# M369 register map
File version: 0.1
TOSHIBA Cortex-M3 MCU
CPU: 
Registers are 32-bit, read-write, reset 0x0 unless marked. A register's access mark holds for its fields unless they carry their own. Offsets are from the block's base; lines under a group give offsets from that group; [hi:lo] are bit positions; {n}, {i} and the like mark numbered series; 'fields as' and 'values as' point back to an identical list; <NAME> marks a mode.

## Memory map
{0x40005000+0x20*n} CANMB{n} size 0x4 (n=0..31) — CAN Controller (TXCAN) Mailbox RAM
0x40005400 CAN size 0x4 — CAN Controller (TXCAN)
0x40006000 HC size 0x58 — USB Host Controller (USBHC)
0x40008000 UDFS size 0x24 — UDC2 AHB Bridge
0x40008200 UDFS2 size 0x8 — UDC2(USB -Spec2.0 Device contoller)
0x4000A000 EM size 0x8 — UDC2 AHB Bridge
0x40040000 SSP0 size 0x28 — Synchronous Serial Port
0x40041000 SSP1 size 0x28 — Synchronous Serial Port
0x40042000 SSP2 size 0x28 — Synchronous Serial Port
0x40048000 UART4 size 0x8 — ARM Prime Cell PL011
0x40049000 UART5 size 0x8 — ARM Prime Cell PL011
0x4004C000 DMAA size 0x10 — DMA Controller
0x4004D000 DMAB size 0x10 — DMA Controller
0x40050000 ADA size 0x20 — Analog-to-Digital Converter (AD)
0x40051000 ADB size 0x20 — Analog-to-Digital Converter (AD)
0x40052000 ADILV size 0xC — Dual ADC Configuration
0x40054000 DA0 size 0x14 — Digital-to-Analog Converter (DA)
0x40055000 DA1 size 0x14 — Digital-to-Analog Converter (DA)
0x4005C000 EXB size 0x4 — External Bus Interface(EXB)
0x400C0000 PA size 0x1C — General Purpose Input_Output Port (PA)
0x400C0100 PB size 0x18 — General Purpose Input_Output Port (PB)
0x400C0200 PC size 0x10 — General Purpose Input_Output Port (PC)
0x400C0300 PD size 0xC — General Purpose Input_Output Port (PD)
0x400C0400 PE size 0x1C — General Purpose Input_Output Port (PE)
0x400C0500 PF size 0x18 — General Purpose Input_Output Port (PF)
0x400C0600 PG size 0x18 — General Purpose Input_Output Port (PG)
0x400C0700 PH size 0x1C — General Purpose Input_Output Port (PH)
0x400C0800 PI size 0x10 — General Purpose Input_Output Port (PI)
0x400C0900 PJ size 0x8 — General Purpose Input_Output Port (PJ)
0x400C0A00 PK size 0x18 — General Purpose Input_Output Port (PK)
0x400C0B00 PL size 0x20 — General Purpose Input_Output Port (PL)
0x400C0C00 PM size 0x10 — General Purpose Input_Output Port (PM)
0x400C0D00 PN size 0x10 — General Purpose Input_Output Port (PN)
{0x400C4000+0x100*n} TB{n} size 0x34 (n=0..7) — 16-bit Timer_Event Counter (TB)
0x400C7000 MT0 size 0x58 — 16-bit Multi-Purpose Timer (MPT-TMR_IGBT)
0x400C7100 MT1 size 0x58 — 16-bit Multi-Purpose Timer (MPT-TMR_IGBT)
0x400C7200 MT2 size 0x58 — 16-bit Multi-Purpose Timer (MPT-TMR_IGBT)
0x400C7300 MT3 size 0x58 — 16-bit Multi-Purpose Timer (MPT-TMR_IGBT)
0x400CC000 RTC size 0x3 — Real Time Clock (RTC)
0x400E0000 SBI0 size 0x18 — Serial Bus Interface (SBI)
0x400E0100 SBI1 size 0x18 — Serial Bus Interface (SBI)
0x400E0200 SBI2 size 0x18 — Serial Bus Interface (SBI)
0x400E1000 SC0 size 0x34 — Serial Channel (SC)
0x400E1100 SC1 size 0x34 — Serial Channel (SC)
0x400E1200 SC2 size 0x34 — Serial Channel (SC)
0x400E1300 SC3 size 0x34 — Serial Channel (SC)
0x400E7000 RMC size 0x38 — Remote Control Signal Preprocessor (RMC)
0x400F1000 OFD size 0x24 — Oscillation Frequency Detector (OFD)
0x400F2000 WD size 0x8 — Watchdog Timer (WD)
0x400F3000 CG size 0x10 — Clock Generator (CG)
0x400F3100 USBPLL size 0xC — Low Voltage detector control register
0x400F3200 TRMOSC size 0x10 — Low Voltage detector control register
0x400F4000 LVD size 0xC — Low Voltage detector control register
0x400F6000 MTPD0 size 0x24 — 16-bit Multi-Purpose Timer (MPT-PMD)
0x400F6100 MTPD1 size 0x24 — 16-bit Multi-Purpose Timer (MPT-PMD)
0x400F7000 EN0 size 0x10 — Encoder Input (ENC)
0x400F7100 EN1 size 0x10 — Encoder Input (ENC)
0x41FFF000 FC — Flash Control (FC)

## CANMB0 — CAN Controller (TXCAN) Mailbox RAM
Base 0x40005000
Same registers: CANMB{n} {0x40005000+0x20*n} (n=1..30)
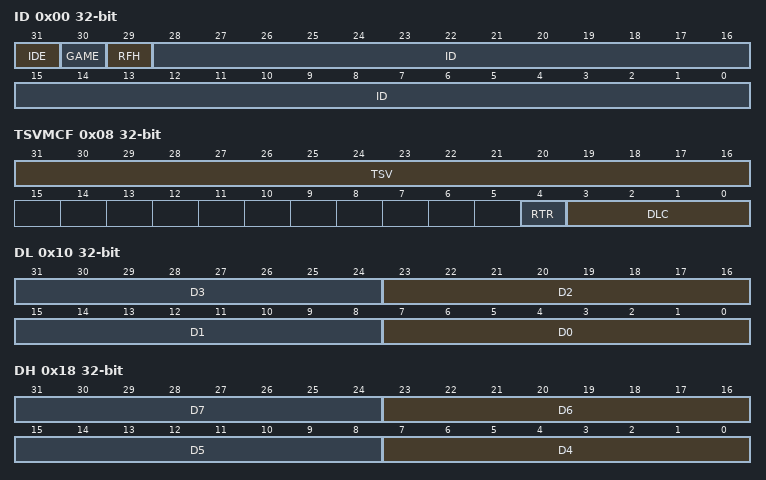
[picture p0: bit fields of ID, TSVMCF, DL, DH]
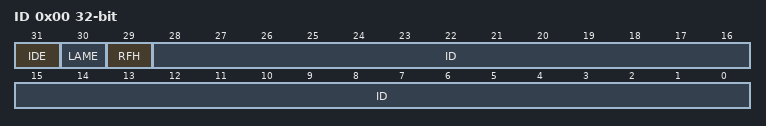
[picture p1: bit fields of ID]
0x00 ID reset not defined — CAN Mailbox Register
  [31] IDE, [30] GAME, [29] RFH, [28:0] ID
0x08 TSVMCF reset not defined — CAN Mailbox Register
  [31:16] TSV, [4] RTR, [3:0] DLC
0x10 DL reset not defined — CAN Mailbox Register
  [8n+7:8n] D{n} (n=0..3)
0x18 DH reset not defined — CAN Mailbox Register
  [8n-25:8n-32] D{n} (n=4..7)

## CANMB31 — CAN Controller (TXCAN) Mailbox RAM
Base 0x400053E0
Registers as CANMB0; these are added or differ:
0x00 ID reset not defined — CAN Mailbox Register
  [31] IDE, [30] LAME, [29] RFH, [28:0] ID
